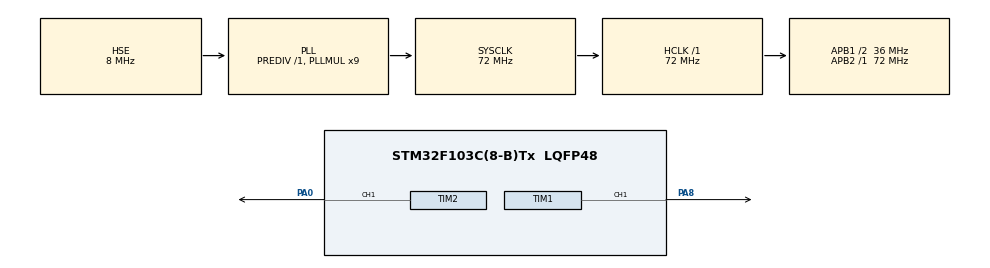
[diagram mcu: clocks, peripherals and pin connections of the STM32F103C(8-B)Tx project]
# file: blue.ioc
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Dma.Request0=TIM2_CH1
Dma.Request1=TIM1_CH1
Dma.TIM1_CH1.1.Direction=DMA_MEMORY_TO_PERIPH
Dma.TIM1_CH1.1.Instance=DMA1_Channel2
Dma.TIM1_CH1.1.MemDataAlignment=DMA_MDATAALIGN_HALFWORD
Dma.TIM1_CH1.1.MemInc=DMA_MINC_ENABLE
Dma.TIM1_CH1.1.Mode=DMA_NORMAL
Dma.TIM1_CH1.1.PeriphDataAlignment=DMA_PDATAALIGN_HALFWORD
Dma.TIM1_CH1.1.PeriphInc=DMA_PINC_DISABLE
Dma.TIM1_CH1.1.Priority=DMA_PRIORITY_LOW
Dma.TIM2_CH1.0.Direction=DMA_MEMORY_TO_PERIPH
Dma.TIM2_CH1.0.Instance=DMA1_Channel5
Dma.TIM2_CH1.0.MemDataAlignment=DMA_MDATAALIGN_HALFWORD
Dma.TIM2_CH1.0.MemInc=DMA_MINC_ENABLE
Dma.TIM2_CH1.0.Mode=DMA_NORMAL
Dma.TIM2_CH1.0.PeriphDataAlignment=DMA_PDATAALIGN_HALFWORD
Dma.TIM2_CH1.0.PeriphInc=DMA_PINC_DISABLE
Dma.TIM2_CH1.0.Priority=DMA_PRIORITY_LOW
Mcu.Family=STM32F1
Mcu.Name=STM32F103C(8-B)Tx
Mcu.Package=LQFP48
NVIC.DMA1_Channel2_IRQn=true\:0\:0\:false\:false\:true\:false\:true\:true
NVIC.DMA1_Channel5_IRQn=true\:0\:0\:false\:false\:true\:false\:true\:true
NVIC.PriorityGroup=NVIC_PRIORITYGROUP_4
PA0-WKUP.Signal=S_TIM2_CH1_ETR
PA13.Mode=Serial_Wire
PA13.Signal=SYS_JTMS-SWDIO
PA14.Mode=Serial_Wire
PA14.Signal=SYS_JTCK-SWCLK
PA8.Signal=S_TIM1_CH1
PC14-OSC32_IN.Mode=LSE-External-Oscillator
PC14-OSC32_IN.Signal=RCC_OSC32_IN
PC15-OSC32_OUT.Mode=LSE-External-Oscillator
PC15-OSC32_OUT.Signal=RCC_OSC32_OUT
PD0-OSC_IN.Mode=HSE-External-Oscillator
PD0-OSC_IN.Signal=RCC_OSC_IN
PD1-OSC_OUT.Mode=HSE-External-Oscillator
PD1-OSC_OUT.Signal=RCC_OSC_OUT
ProjectManager.HeapSize=0x200
ProjectManager.StackSize=0x400
ProjectManager.TargetToolchain=STM32CubeIDE
RCC.AHBFreq_Value=72000000
RCC.APB1CLKDivider=RCC_HCLK_DIV2
RCC.APB1Freq_Value=36000000
RCC.APB1TimFreq_Value=72000000
RCC.APB2Freq_Value=72000000
RCC.APB2TimFreq_Value=72000000
RCC.HCLKFreq_Value=72000000
RCC.PLLMUL=RCC_PLL_MUL9
RCC.PLLSourceVirtual=RCC_PLLSOURCE_HSE
RCC.SYSCLKFreq_VALUE=72000000
RCC.SYSCLKSource=RCC_SYSCLKSOURCE_PLLCLK
RCC.USBFreq_Value=72000000
SH.S_TIM1_CH1.0=TIM1_CH1,PWM Generation1 CH1
SH.S_TIM2_CH1_ETR.0=TIM2_CH1,PWM Generation1 CH1
TIM1.Channel-PWM\ Generation1\ CH1=TIM_CHANNEL_1
TIM2.Channel-PWM\ Generation1\ CH1=TIM_CHANNEL_1
TIM2.Period=72-1
VP_TIM1_VS_ClockSourceINT.Mode=Internal
VP_TIM2_VS_ClockSourceINT.Mode=Internal
board=custom

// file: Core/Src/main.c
/* USER CODE BEGIN Header */
/**
 ******************************************************************************
 * @file           : main.c
 * @brief          : Main program body
 ******************************************************************************
 * @attention
 *
 * Copyright (c) 2024 STMicroelectronics.
 * All rights reserved.
 *
 * This software is licensed under terms that can be found in the LICENSE file
 * in the root directory of this software component.
 * If no LICENSE file comes with this software, it is provided AS-IS.
 *
 ******************************************************************************
 */
/* USER CODE END Header */
#include "main.h"

/* USER CODE BEGIN Includes */
#define LED_MAX 16
#define USE_BRIGHTNESS 0
#define FALSE  1
#define TRUE  0
/* USER CODE END Includes */

TIM_HandleTypeDef htim1;
TIM_HandleTypeDef htim2;
DMA_HandleTypeDef hdma_tim1_ch1;
DMA_HandleTypeDef hdma_tim2_ch1;

void SystemClock_Config(void);
static void MX_GPIO_Init(void);
static void MX_DMA_Init(void);
static void MX_TIM2_Init(void);
static void MX_TIM1_Init(void);

/* USER CODE BEGIN 0 */

uint16_t pwmData[LED_MAX * 24 + 50];
uint8_t led_Data[LED_MAX][3];
uint8_t running = FALSE;
uint8_t brightness = 0;
uint8_t direction = TRUE;

void setLed(uint8_t LEDNum, uint8_t Red, uint8_t Green, uint8_t Blue) {
	led_Data[LEDNum][0] = Green;
	led_Data[LEDNum][1] = Red;
	led_Data[LEDNum][2] = Blue;
}

void send() {
	for (uint8_t led = 0; led != LED_MAX; led++) {
		uint32_t data = (led_Data[led][0] << 16) | (led_Data[led][1] << 8)
				| led_Data[led][2];
		for (int i = 23; i >= 0; i--) {
			pwmData[(24 - i + led * 24)] = (data & (1 << i)) ? 60 : 30;
		}
	}
	uint32_t start = LED_MAX * 24 - 1;
	for (uint32_t i = start; i < start + 50; i++) {
		pwmData[i] = 0;
	}

	HAL_TIM_PWM_Start_DMA(&htim2, TIM_CHANNEL_1, (uint32_t*) pwmData,
	LED_MAX * 24);
	running = TRUE;

}

void sendSingle(uint8_t Green, uint8_t Red, uint8_t Blue) {
	running = TRUE;
	uint32_t data = (Green << 16) | (Red << 8) | Blue;
	for (int i = 23; i >= 0; i--) {
		pwmData[i] = (data & (1 << i)) ? 66 : 33;
	}

	// HAL_TIM_PWM_Start_DMA(&htim1, TIM_CHANNEL_1, (uint32_t*) pwmData, 24);
	HAL_TIM_PWM_Start_DMA(&htim2, TIM_CHANNEL_1, (uint32_t*) pwmData, 24);
	running = TRUE;
}

void HAL_TIM_PWM_PulseFinishedCallback(TIM_HandleTypeDef *htim) {
	//HAL_TIM_PWM_Stop_DMA(&htim1, TIM_CHANNEL_1);
	HAL_TIM_PWM_Stop_DMA(&htim2, TIM_CHANNEL_1);
	running = FALSE;
}
/* USER CODE END 0 */

int main(void) {

	/* MCU Configuration--------------------------------------------------------*/

	/* Reset of all peripherals, Initializes the Flash interface and the Systick. */
	HAL_Init();

	/* Configure the system clock */
	SystemClock_Config();

	/* Initialize all configured peripherals */
	MX_GPIO_Init();
	MX_DMA_Init();
	MX_TIM2_Init();
	MX_TIM1_Init();

	/* Infinite loop */
	/* USER CODE BEGIN WHILE */

	while (1) {

		//setLed(0, 255, 255, 255); //RED
		//setLed(1, 0, 0, 0); //RED
		//	setLed(2, 255, 255, 255); //RED
//		setLed(1, 0, 255, 0); //BLUE
//		setLed(2, 0, 0, 255); //GREEN
//
//		setLed(4, 200, 200, 0); // RED + BLUE
//		setLed(5, 0, 200, 200); // BLUE + GREEN
//		setLed(6, 160, 0, 160); // GREEN + RED

//		setLed(9, 190, 0, 0);
//		setLed(10, 200, 0, 0);
//		setLed(11, 210, 0, 0);
//		setLed(12, 220, 0, 0);
//		setLed(13, 230, 0, 0);
//		setLed(14, 240, 0, 0);
//		setLed(15, 260, 0, 0);
		setLed(0, brightness, 0, 0);

		setLed(5, 0, brightness, 0);

		setLed(10, 0, 0, brightness);
		send();
		while (running) {
		}
		if (direction)
			brightness--;
		else
			brightness++;

		if (brightness >= 255 || brightness <= 0)
			direction  = !direction;
		HAL_Delay(10);
		//	send(0, 0, 255);
		//	HAL_Delay(1000);
		/* USER CODE END WHILE */

	}
}

void SystemClock_Config(void) {
	RCC_OscInitTypeDef RCC_OscInitStruct = { 0 };
	RCC_ClkInitTypeDef RCC_ClkInitStruct = { 0 };

	/** Initializes the RCC Oscillators according to the specified parameters
	 * in the RCC_OscInitTypeDef structure.
	 */
	RCC_OscInitStruct.OscillatorType = RCC_OSCILLATORTYPE_HSE;
	RCC_OscInitStruct.HSEState = RCC_HSE_ON;
	RCC_OscInitStruct.HSEPredivValue = RCC_HSE_PREDIV_DIV1;
	RCC_OscInitStruct.HSIState = RCC_HSI_ON;
	RCC_OscInitStruct.PLL.PLLState = RCC_PLL_ON;
	RCC_OscInitStruct.PLL.PLLSource = RCC_PLLSOURCE_HSE;
	RCC_OscInitStruct.PLL.PLLMUL = RCC_PLL_MUL9;
	if (HAL_RCC_OscConfig(&RCC_OscInitStruct) != HAL_OK) {
		Error_Handler();
	}

	/** Initializes the CPU, AHB and APB buses clocks
	 */
	RCC_ClkInitStruct.ClockType = RCC_CLOCKTYPE_HCLK | RCC_CLOCKTYPE_SYSCLK
			| RCC_CLOCKTYPE_PCLK1 | RCC_CLOCKTYPE_PCLK2;
	RCC_ClkInitStruct.SYSCLKSource = RCC_SYSCLKSOURCE_PLLCLK;
	RCC_ClkInitStruct.AHBCLKDivider = RCC_SYSCLK_DIV1;
	RCC_ClkInitStruct.APB1CLKDivider = RCC_HCLK_DIV2;
	RCC_ClkInitStruct.APB2CLKDivider = RCC_HCLK_DIV1;

	if (HAL_RCC_ClockConfig(&RCC_ClkInitStruct, FLASH_LATENCY_2) != HAL_OK) {
		Error_Handler();
	}
}

static void MX_TIM1_Init(void) {

	TIM_ClockConfigTypeDef sClockSourceConfig = { 0 };
	TIM_MasterConfigTypeDef sMasterConfig = { 0 };
	TIM_OC_InitTypeDef sConfigOC = { 0 };
	TIM_BreakDeadTimeConfigTypeDef sBreakDeadTimeConfig = { 0 };

	htim1.Instance = TIM1;
	htim1.Init.Prescaler = 0;
	htim1.Init.CounterMode = TIM_COUNTERMODE_UP;
	htim1.Init.Period = 65535;
	htim1.Init.ClockDivision = TIM_CLOCKDIVISION_DIV1;
	htim1.Init.RepetitionCounter = 0;
	htim1.Init.AutoReloadPreload = TIM_AUTORELOAD_PRELOAD_DISABLE;
	if (HAL_TIM_Base_Init(&htim1) != HAL_OK) {
		Error_Handler();
	}
	sClockSourceConfig.ClockSource = TIM_CLOCKSOURCE_INTERNAL;
	if (HAL_TIM_ConfigClockSource(&htim1, &sClockSourceConfig) != HAL_OK) {
		Error_Handler();
	}
	if (HAL_TIM_PWM_Init(&htim1) != HAL_OK) {
		Error_Handler();
	}
	sMasterConfig.MasterOutputTrigger = TIM_TRGO_RESET;
	sMasterConfig.MasterSlaveMode = TIM_MASTERSLAVEMODE_DISABLE;
	if (HAL_TIMEx_MasterConfigSynchronization(&htim1, &sMasterConfig)
			!= HAL_OK) {
		Error_Handler();
	}
	sConfigOC.OCMode = TIM_OCMODE_PWM1;
	sConfigOC.Pulse = 0;
	sConfigOC.OCPolarity = TIM_OCPOLARITY_HIGH;
	sConfigOC.OCNPolarity = TIM_OCNPOLARITY_HIGH;
	sConfigOC.OCFastMode = TIM_OCFAST_DISABLE;
	sConfigOC.OCIdleState = TIM_OCIDLESTATE_RESET;
	sConfigOC.OCNIdleState = TIM_OCNIDLESTATE_RESET;
	if (HAL_TIM_PWM_ConfigChannel(&htim1, &sConfigOC, TIM_CHANNEL_1)
			!= HAL_OK) {
		Error_Handler();
	}
	sBreakDeadTimeConfig.OffStateRunMode = TIM_OSSR_DISABLE;
	sBreakDeadTimeConfig.OffStateIDLEMode = TIM_OSSI_DISABLE;
	sBreakDeadTimeConfig.LockLevel = TIM_LOCKLEVEL_OFF;
	sBreakDeadTimeConfig.DeadTime = 0;
	sBreakDeadTimeConfig.BreakState = TIM_BREAK_DISABLE;
	sBreakDeadTimeConfig.BreakPolarity = TIM_BREAKPOLARITY_HIGH;
	sBreakDeadTimeConfig.AutomaticOutput = TIM_AUTOMATICOUTPUT_DISABLE;
	if (HAL_TIMEx_ConfigBreakDeadTime(&htim1, &sBreakDeadTimeConfig)
			!= HAL_OK) {
		Error_Handler();
	}
	HAL_TIM_MspPostInit(&htim1);

}

static void MX_TIM2_Init(void) {

	TIM_ClockConfigTypeDef sClockSourceConfig = { 0 };
	TIM_MasterConfigTypeDef sMasterConfig = { 0 };
	TIM_OC_InitTypeDef sConfigOC = { 0 };

	htim2.Instance = TIM2;
	htim2.Init.Prescaler = 0;
	htim2.Init.CounterMode = TIM_COUNTERMODE_UP;
	htim2.Init.Period = 90 - 1;
	htim2.Init.ClockDivision = TIM_CLOCKDIVISION_DIV1;
	htim2.Init.AutoReloadPreload = TIM_AUTORELOAD_PRELOAD_DISABLE;
	if (HAL_TIM_Base_Init(&htim2) != HAL_OK) {
		Error_Handler();
	}
	sClockSourceConfig.ClockSource = TIM_CLOCKSOURCE_INTERNAL;
	if (HAL_TIM_ConfigClockSource(&htim2, &sClockSourceConfig) != HAL_OK) {
		Error_Handler();
	}
	if (HAL_TIM_PWM_Init(&htim2) != HAL_OK) {
		Error_Handler();
	}
	sMasterConfig.MasterOutputTrigger = TIM_TRGO_RESET;
	sMasterConfig.MasterSlaveMode = TIM_MASTERSLAVEMODE_DISABLE;
	if (HAL_TIMEx_MasterConfigSynchronization(&htim2, &sMasterConfig)
			!= HAL_OK) {
		Error_Handler();
	}
	sConfigOC.OCMode = TIM_OCMODE_PWM1;
	sConfigOC.Pulse = 0;
	sConfigOC.OCPolarity = TIM_OCPOLARITY_HIGH;
	sConfigOC.OCNPolarity = TIM_OCNPOLARITY_HIGH;
	sConfigOC.OCFastMode = TIM_OCFAST_DISABLE;
	sConfigOC.OCIdleState = TIM_OCIDLESTATE_RESET;
	sConfigOC.OCNIdleState = TIM_OCNIDLESTATE_RESET;
	if (HAL_TIM_PWM_ConfigChannel(&htim2, &sConfigOC, TIM_CHANNEL_1)
			!= HAL_OK) {
		Error_Handler();
	}
	HAL_TIM_MspPostInit(&htim2);

}

static void MX_DMA_Init(void) {

	/* DMA controller clock enable */
	__HAL_RCC_DMA1_CLK_ENABLE();

	/* DMA interrupt init */
	/* DMA1_Channel2_IRQn interrupt configuration */
	HAL_NVIC_SetPriority(DMA1_Channel2_IRQn, 0, 0);
	HAL_NVIC_EnableIRQ(DMA1_Channel2_IRQn);
	/* DMA1_Channel5_IRQn interrupt configuration */
	HAL_NVIC_SetPriority(DMA1_Channel5_IRQn, 0, 0);
	HAL_NVIC_EnableIRQ(DMA1_Channel5_IRQn);

}

static void MX_GPIO_Init(void) {

	/* GPIO Ports Clock Enable */
	__HAL_RCC_GPIOC_CLK_ENABLE();
	__HAL_RCC_GPIOD_CLK_ENABLE();
	__HAL_RCC_GPIOA_CLK_ENABLE();

}

void Error_Handler(void) {
	__disable_irq();
	while (1) {
	}
}
